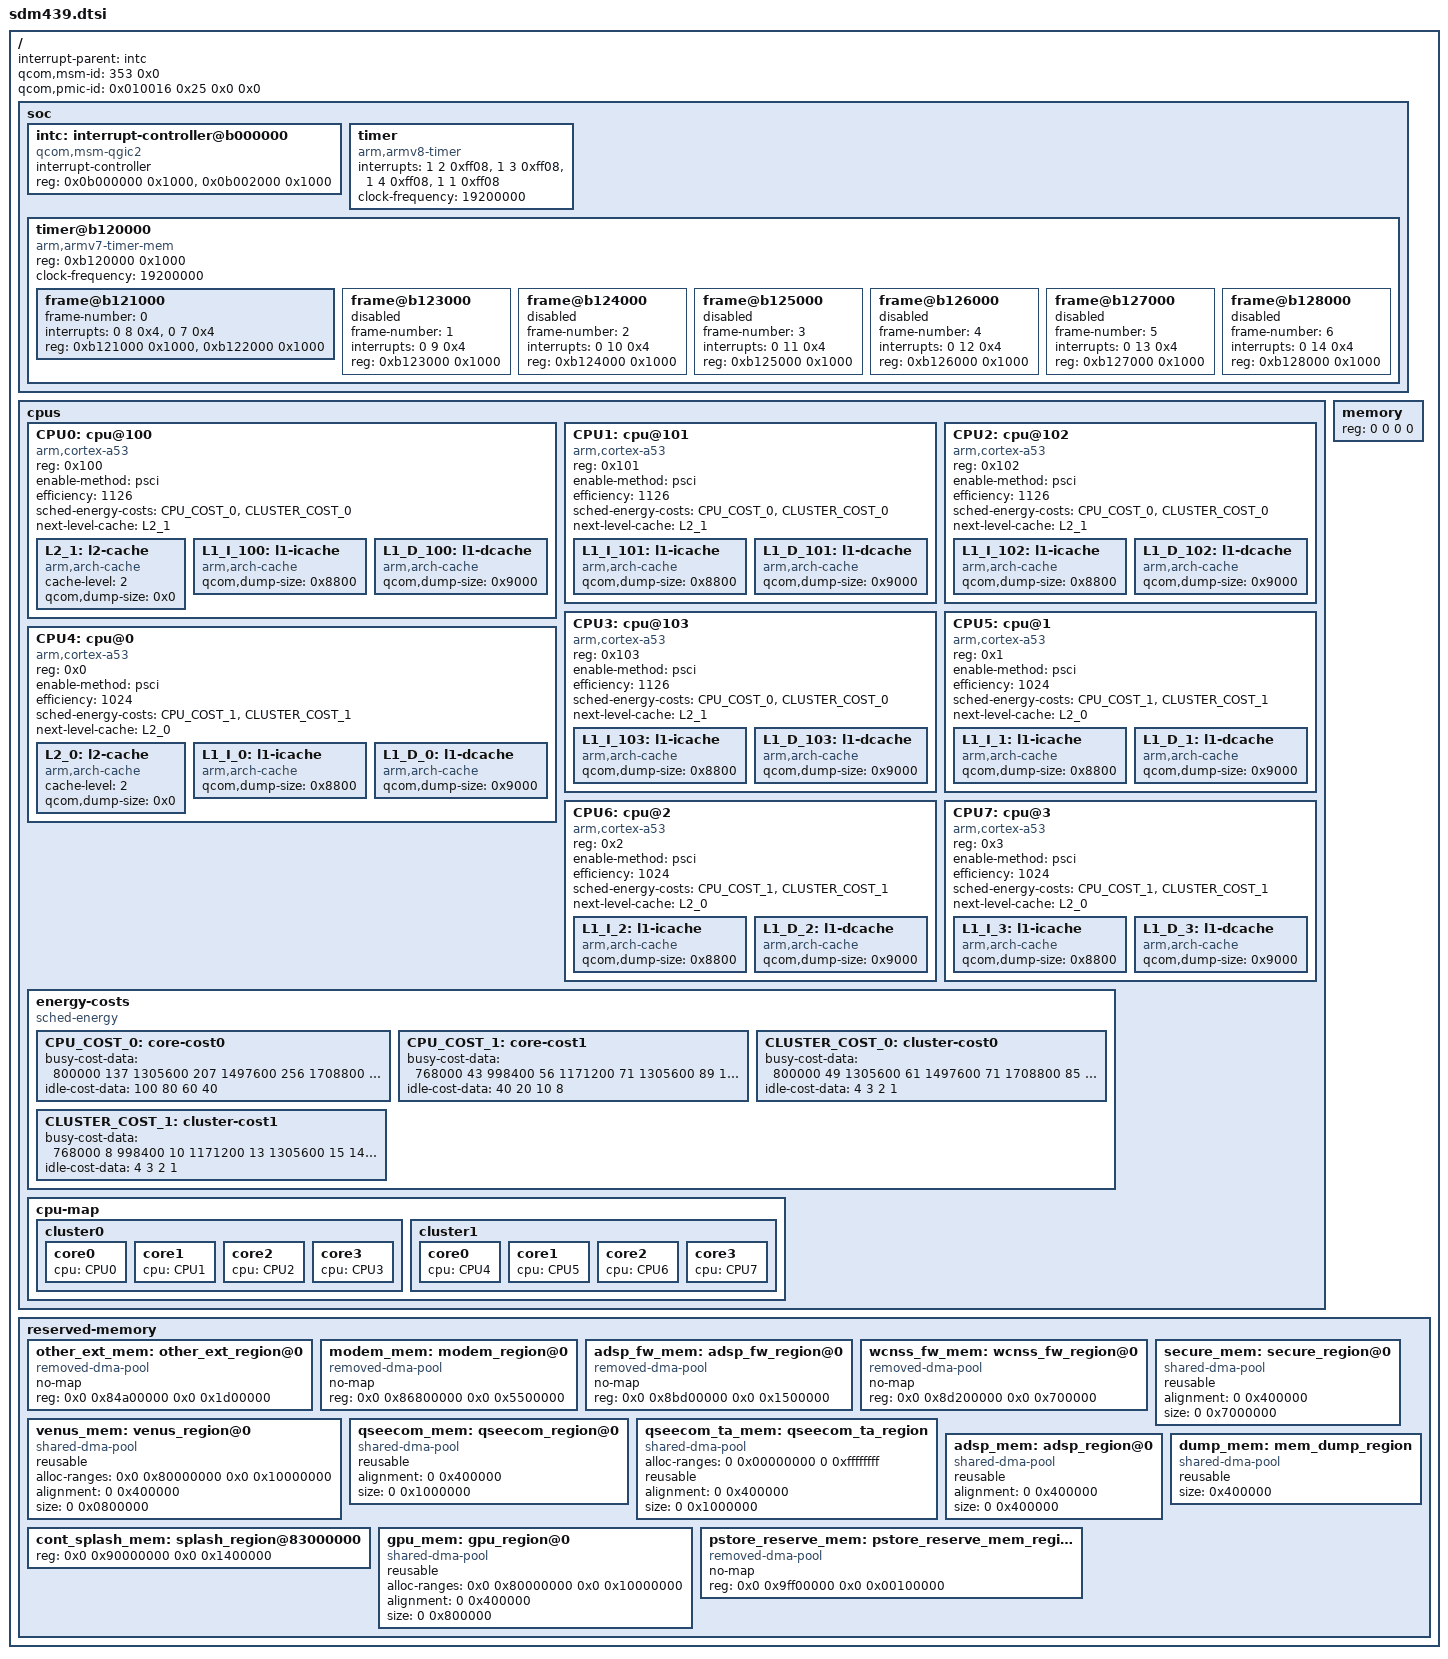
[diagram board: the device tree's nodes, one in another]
#include <dt-bindings/interrupt-controller/arm-gic.h>

/ {
	interrupt-parent = <&intc>;	

	qcom,msm-id = <353 0x0>;
	qcom,pmic-id = <0x010016 0x25 0x0 0x0>;

	#address-cells = <2>;
	#size-cells = <2>;

	soc {
		#address-cells = <1>;
		#size-cells = <1>;

		intc: interrupt-controller@b000000 {
			compatible = "qcom,msm-qgic2";
			interrupt-controller;
			#interrupt-cells = <3>;
			reg = <0x0b000000 0x1000>, <0x0b002000 0x1000>;
		};

		timer {
			compatible = "arm,armv8-timer";
			interrupts = <1 2 0xff08>,
				<1 3 0xff08>,
				<1 4 0xff08>,
				<1 1 0xff08>;
			clock-frequency = <19200000>;
		};

		timer@b120000 {
			#address-cells = <1>;
			#size-cells = <1>;
			compatible = "arm,armv7-timer-mem";
			reg = <0xb120000 0x1000>;
			clock-frequency = <19200000>;

			frame@b121000 {
				frame-number = <0>;
				interrupts = <0 8 0x4>,
						 <0 7 0x4>;
				reg = <0xb121000 0x1000>,
					  <0xb122000 0x1000>;
			};

			frame@b123000 {
				frame-number = <1>;
				interrupts = <0 9 0x4>;
				reg = <0xb123000 0x1000>;
				status = "disabled";
			};

			frame@b124000 {
				frame-number = <2>;
				interrupts = <0 10 0x4>;
				reg = <0xb124000 0x1000>;
				status = "disabled";
			};

			frame@b125000 {
				frame-number = <3>;
				interrupts = <0 11 0x4>;
				reg = <0xb125000 0x1000>;
				status = "disabled";
			};

			frame@b126000 {
				frame-number = <4>;
				interrupts = <0 12 0x4>;
				reg = <0xb126000 0x1000>;
				status = "disabled";
			};

			frame@b127000 {
				frame-number = <5>;
				interrupts = <0 13 0x4>;
				reg = <0xb127000 0x1000>;
				status = "disabled";
			};

			frame@b128000 {
				frame-number = <6>;
				interrupts = <0 14 0x4>;
				reg = <0xb128000 0x1000>;
				status = "disabled";
			};
		};
	};

	cpus {
		#address-cells = <1>;
		#size-cells = <0>;

		CPU0: cpu@100 {
			device_type = "cpu";
			compatible = "arm,cortex-a53";
			reg = <0x100>;
			enable-method = "psci";
			efficiency = <1126>;
			sched-energy-costs = <&CPU_COST_0 &CLUSTER_COST_0>;
			next-level-cache = <&L2_1>;
			#cooling-cells = <2>;

			L2_1: l2-cache {
				compatible = "arm,arch-cache";
				cache-level = <2>;
				qcom,dump-size = <0x0>;
			};

			L1_I_100: l1-icache {
				compatible = "arm,arch-cache";
				qcom,dump-size = <0x8800>;
			};

			L1_D_100: l1-dcache {
				compatible = "arm,arch-cache";
				qcom,dump-size = <0x9000>;
			};
		};

		CPU1: cpu@101 {
			device_type = "cpu";
			compatible = "arm,cortex-a53";
			reg = <0x101>;
			enable-method = "psci";
			efficiency = <1126>;
			sched-energy-costs = <&CPU_COST_0 &CLUSTER_COST_0>;
			next-level-cache = <&L2_1>;
			#cooling-cells = <2>;

			L1_I_101: l1-icache {
				compatible = "arm,arch-cache";
				qcom,dump-size = <0x8800>;
			};

			L1_D_101: l1-dcache {
				compatible = "arm,arch-cache";
				qcom,dump-size = <0x9000>;
			};
		};

		CPU2: cpu@102 {
			device_type = "cpu";
			compatible = "arm,cortex-a53";
			reg = <0x102>;
			enable-method = "psci";
			efficiency = <1126>;
			sched-energy-costs = <&CPU_COST_0 &CLUSTER_COST_0>;
			next-level-cache = <&L2_1>;
			#cooling-cells = <2>;

			L1_I_102: l1-icache {
				compatible = "arm,arch-cache";
				qcom,dump-size = <0x8800>;
			};

			L1_D_102: l1-dcache {
				compatible = "arm,arch-cache";
				qcom,dump-size = <0x9000>;
			};
		};

		CPU3: cpu@103 {
			device_type = "cpu";
			compatible = "arm,cortex-a53";
			reg = <0x103>;
			enable-method = "psci";
			efficiency = <1126>;
			sched-energy-costs = <&CPU_COST_0 &CLUSTER_COST_0>;
			next-level-cache = <&L2_1>;
			#cooling-cells = <2>;

			L1_I_103: l1-icache {
				compatible = "arm,arch-cache";
				qcom,dump-size = <0x8800>;
			};

			L1_D_103: l1-dcache {
				compatible = "arm,arch-cache";
				qcom,dump-size = <0x9000>;
			};
		};

		CPU4: cpu@0 {
			device_type = "cpu";
			compatible = "arm,cortex-a53";
			reg = <0x0>;
			enable-method = "psci";
			efficiency = <1024>;
			sched-energy-costs = <&CPU_COST_1 &CLUSTER_COST_1>;
			next-level-cache = <&L2_0>;
			#cooling-cells = <2>;

			L2_0: l2-cache {
				compatible = "arm,arch-cache";
				cache-level = <2>;
				qcom,dump-size = <0x0>;
			};

			L1_I_0: l1-icache {
				compatible = "arm,arch-cache";
				qcom,dump-size = <0x8800>;
			};

			L1_D_0: l1-dcache {
				compatible = "arm,arch-cache";
				qcom,dump-size = <0x9000>;
			};
		};

		CPU5: cpu@1 {
			device_type = "cpu";
			compatible = "arm,cortex-a53";
			reg = <0x1>;
			enable-method = "psci";
			efficiency = <1024>;
			sched-energy-costs = <&CPU_COST_1 &CLUSTER_COST_1>;
			next-level-cache = <&L2_0>;
			#cooling-cells = <2>;

			L1_I_1: l1-icache {
				compatible = "arm,arch-cache";
				qcom,dump-size = <0x8800>;
			};

			L1_D_1: l1-dcache {
				compatible = "arm,arch-cache";
				qcom,dump-size = <0x9000>;
			};
		};

		CPU6: cpu@2 {
			device_type = "cpu";
			compatible = "arm,cortex-a53";
			reg = <0x2>;
			enable-method = "psci";
			efficiency = <1024>;
			sched-energy-costs = <&CPU_COST_1 &CLUSTER_COST_1>;
			next-level-cache = <&L2_0>;
			#cooling-cells = <2>;

			L1_I_2: l1-icache {
				compatible = "arm,arch-cache";
				qcom,dump-size = <0x8800>;
			};

			L1_D_2: l1-dcache {
				compatible = "arm,arch-cache";
				qcom,dump-size = <0x9000>;
			};
		};

		CPU7: cpu@3 {
			device_type = "cpu";
			compatible = "arm,cortex-a53";
			reg = <0x3>;
			enable-method = "psci";
			efficiency = <1024>;
			sched-energy-costs = <&CPU_COST_1 &CLUSTER_COST_1>;
			next-level-cache = <&L2_0>;
			#cooling-cells = <2>;

			L1_I_3: l1-icache {
				compatible = "arm,arch-cache";
				qcom,dump-size = <0x8800>;
			};

			L1_D_3: l1-dcache {
				compatible = "arm,arch-cache";
				qcom,dump-size = <0x9000>;
			};
		};

		energy-costs {
			compatible = "sched-energy";

			CPU_COST_0: core-cost0 {
				busy-cost-data = <
					800000	137
					1305600	207
					1497600	256
					1708800	327
					1804800	343
					1958400	445
					2016000	470
				>;
				idle-cost-data = <
					100 80 60 40
				>;
			};
		
			CPU_COST_1: core-cost1 {
				busy-cost-data = <
					768000 43
					998400 56
					1171200	71
					1305600	89
					1459200	120
				>;
		
				idle-cost-data = <
					40 20 10 8
				>;
			};
		
			CLUSTER_COST_0: cluster-cost0 {
				busy-cost-data = <
					800000 49
					1305600	61
					1497600	71
					1708800	85
					1804800	88
					1958400	110
					2016000	120
				>;
		
				idle-cost-data = <
					4 3 2 1
				>;
			};

			CLUSTER_COST_1: cluster-cost1 {
				busy-cost-data = <
					768000 8
					998400 10
					1171200	13
					1305600	15
					1459200	20
				>;

				idle-cost-data = <
					4 3 2 1
				>;
			};
		};

		cpu-map {
			cluster0 {
				core0 {
					cpu = <&CPU0>;
				};

				core1 {
					cpu = <&CPU1>;
				};

				core2 {
					cpu = <&CPU2>;
				};

				core3 {
					cpu = <&CPU3>;
				};
			};

			cluster1 {
				core0 {
					cpu = <&CPU4>;
				};

				core1 {
					cpu = <&CPU5>;
				};

				core2 {
					cpu = <&CPU6>;
				};

				core3 {
					cpu = <&CPU7>;
				};
			};
		};
	};

	memory {
		device_type = "memory";
		reg = <0 0 0 0>;
	};

	reserved-memory {
		#address-cells = <2>;
		#size-cells = <2>;
		ranges;

		other_ext_mem: other_ext_region@0 {
			compatible = "removed-dma-pool";
			no-map;
			reg = <0x0 0x84a00000 0x0 0x1d00000>;
		};

		modem_mem: modem_region@0 {
			compatible = "removed-dma-pool";
			no-map;
			reg = <0x0 0x86800000 0x0 0x5500000>;
		};

		adsp_fw_mem: adsp_fw_region@0 {
			compatible = "removed-dma-pool";
			no-map;
			reg = <0x0 0x8bd00000 0x0 0x1500000>;
		};

		wcnss_fw_mem: wcnss_fw_region@0 {
			compatible = "removed-dma-pool";
			no-map;
			reg = <0x0 0x8d200000 0x0 0x700000>;
		};


		venus_mem: venus_region@0 {
			compatible = "shared-dma-pool";
			reusable;
			alloc-ranges = <0x0 0x80000000 0x0 0x10000000>;
			alignment = <0 0x400000>;
			size = <0 0x0800000>;
		};

		secure_mem: secure_region@0 {
			compatible = "shared-dma-pool";
			reusable;
			alignment = <0 0x400000>;
			size = <0 0x7000000>;
		};

		qseecom_mem: qseecom_region@0 {
			compatible = "shared-dma-pool";
			reusable;
			alignment = <0 0x400000>;
			size = <0 0x1000000>;
		};

		qseecom_ta_mem: qseecom_ta_region {
			 compatible = "shared-dma-pool";
			 alloc-ranges = <0 0x00000000 0 0xffffffff>;
			 reusable;
			 alignment = <0 0x400000>;
			 size = <0 0x1000000>;
		};

		adsp_mem: adsp_region@0 {
			compatible = "shared-dma-pool";
			reusable;
			alignment = <0 0x400000>;
			size = <0 0x400000>;
		};

		cont_splash_mem: splash_region@83000000 {
			reg = <0x0 0x90000000 0x0 0x1400000>;
		};

		dump_mem: mem_dump_region {
			compatible = "shared-dma-pool";
			reusable;
			size = <0x400000>;
		};

		gpu_mem: gpu_region@0 {
			compatible = "shared-dma-pool";
			reusable;
			alloc-ranges = <0x0 0x80000000 0x0 0x10000000>;
			alignment = <0 0x400000>;
			size = <0 0x800000>;
		};

		pstore_reserve_mem: pstore_reserve_mem_region@0 {
			compatible = "removed-dma-pool";
			no-map;
			reg = <0x0 0x9ff00000 0x0 0x00100000>;
		};
	};
};
